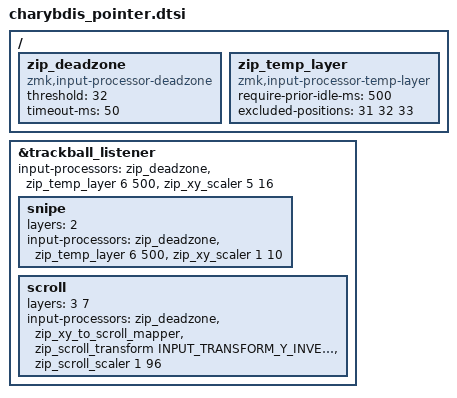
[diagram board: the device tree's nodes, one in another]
#include <input/processors.dtsi>
#include <dt-bindings/zmk/input_transform.h>

/ {
	/*
	 * deadzone filter: suppresses typing vibration micro-movements
	 * requires cumulative movement >= 32 counts before passing events through (1600 CPI)
	 */
	zip_deadzone: zip_deadzone {
		compatible = "zmk,input-processor-deadzone";
		#input-processor-cells = <0>;
		threshold = <32>;
		timeout-ms = <50>;
	};

	/* 
	 * auto-mouse layer definition
	 * Layer 6 is MOUSE in colemak_dh.keymap
	 */
	zip_temp_layer: zip_temp_layer {
		compatible = "zmk,input-processor-temp-layer";
		#input-processor-cells = <2>;
		require-prior-idle-ms = <500>;
		excluded-positions = <31 32 33>; /* Only H, comma, period */
	};
};

&trackball_listener {
	/* base processor chain on all layers */
	input-processors = <
		&zip_deadzone
		&zip_temp_layer 6 500
		&zip_xy_scaler 5 16 /* scale cursor speed (1600 CPI) */
	>;

	snipe {
		/* slow cursor on NAV layer */
		layers = <2>;
		input-processors = <
			&zip_deadzone
			&zip_temp_layer 6 500
			&zip_xy_scaler 1 10
		>;
	};

	scroll {
		/* trackball scroll on NUM and SCROLL layer */
		layers = <3 7>;
		input-processors = <
			&zip_deadzone
			&zip_xy_to_scroll_mapper /* convert xy movement to scroll events */
			&zip_scroll_transform INPUT_TRANSFORM_Y_INVERT /* invert vertical scroll direction */
			&zip_scroll_scaler 1 96 /* scale scroll speed (1600 CPI) */
		>;
	};
};
